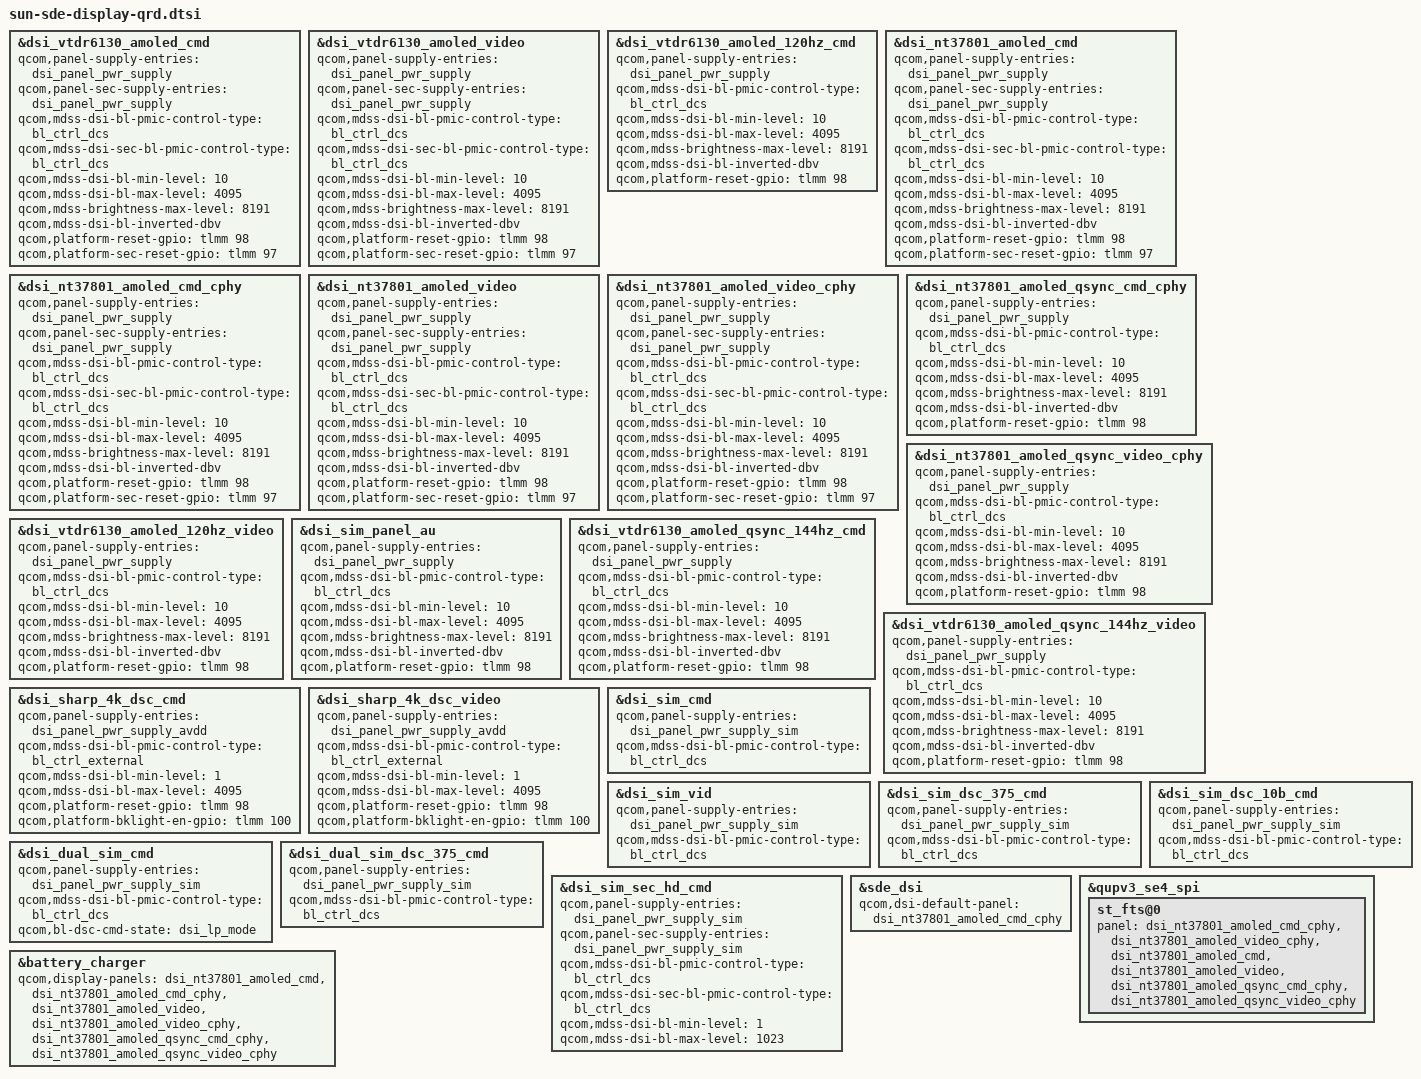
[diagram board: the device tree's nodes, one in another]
// SPDX-License-Identifier: BSD-3-Clause
/*
 * Copyright (c) 2023-2024, Qualcomm Innovation Center, Inc. All rights reserved.
 */

#include "sun-sde-display.dtsi"

&dsi_vtdr6130_amoled_cmd {
	qcom,panel-supply-entries = <&dsi_panel_pwr_supply>;
	qcom,panel-sec-supply-entries = <&dsi_panel_pwr_supply>;
	qcom,mdss-dsi-bl-pmic-control-type = "bl_ctrl_dcs";
	qcom,mdss-dsi-sec-bl-pmic-control-type = "bl_ctrl_dcs";
	qcom,mdss-dsi-bl-min-level = <10>;
	qcom,mdss-dsi-bl-max-level = <4095>;
	qcom,mdss-brightness-max-level = <8191>;
	qcom,mdss-dsi-bl-inverted-dbv;
	qcom,platform-reset-gpio = <&tlmm 98 0>;
	qcom,platform-sec-reset-gpio = <&tlmm 97 0>;
};

&dsi_vtdr6130_amoled_video {
	qcom,panel-supply-entries = <&dsi_panel_pwr_supply>;
	qcom,panel-sec-supply-entries = <&dsi_panel_pwr_supply>;
	qcom,mdss-dsi-bl-pmic-control-type = "bl_ctrl_dcs";
	qcom,mdss-dsi-sec-bl-pmic-control-type = "bl_ctrl_dcs";
	qcom,mdss-dsi-bl-min-level = <10>;
	qcom,mdss-dsi-bl-max-level = <4095>;
	qcom,mdss-brightness-max-level = <8191>;
	qcom,mdss-dsi-bl-inverted-dbv;
	qcom,platform-reset-gpio = <&tlmm 98 0>;
	qcom,platform-sec-reset-gpio = <&tlmm 97 0>;
};

&dsi_vtdr6130_amoled_120hz_cmd {
	qcom,panel-supply-entries = <&dsi_panel_pwr_supply>;
	qcom,mdss-dsi-bl-pmic-control-type = "bl_ctrl_dcs";
	qcom,mdss-dsi-bl-min-level = <10>;
	qcom,mdss-dsi-bl-max-level = <4095>;
	qcom,mdss-brightness-max-level = <8191>;
	qcom,mdss-dsi-bl-inverted-dbv;
	qcom,platform-reset-gpio = <&tlmm 98 0>;
};

&dsi_nt37801_amoled_cmd {
	qcom,panel-supply-entries = <&dsi_panel_pwr_supply>;
	qcom,panel-sec-supply-entries = <&dsi_panel_pwr_supply>;
	qcom,mdss-dsi-bl-pmic-control-type = "bl_ctrl_dcs";
	qcom,mdss-dsi-sec-bl-pmic-control-type = "bl_ctrl_dcs";
	qcom,mdss-dsi-bl-min-level = <10>;
	qcom,mdss-dsi-bl-max-level = <4095>;
	qcom,mdss-brightness-max-level = <8191>;
	qcom,mdss-dsi-bl-inverted-dbv;
	qcom,platform-reset-gpio = <&tlmm 98 0>;
	qcom,platform-sec-reset-gpio = <&tlmm 97 0>;
};

&dsi_nt37801_amoled_cmd_cphy {
	qcom,panel-supply-entries = <&dsi_panel_pwr_supply>;
	qcom,panel-sec-supply-entries = <&dsi_panel_pwr_supply>;
	qcom,mdss-dsi-bl-pmic-control-type = "bl_ctrl_dcs";
	qcom,mdss-dsi-sec-bl-pmic-control-type = "bl_ctrl_dcs";
	qcom,mdss-dsi-bl-min-level = <10>;
	qcom,mdss-dsi-bl-max-level = <4095>;
	qcom,mdss-brightness-max-level = <8191>;
	qcom,mdss-dsi-bl-inverted-dbv;
	qcom,platform-reset-gpio = <&tlmm 98 0>;
	qcom,platform-sec-reset-gpio = <&tlmm 97 0>;
};

&dsi_nt37801_amoled_video {
	qcom,panel-supply-entries = <&dsi_panel_pwr_supply>;
	qcom,panel-sec-supply-entries = <&dsi_panel_pwr_supply>;
	qcom,mdss-dsi-bl-pmic-control-type = "bl_ctrl_dcs";
	qcom,mdss-dsi-sec-bl-pmic-control-type = "bl_ctrl_dcs";
	qcom,mdss-dsi-bl-min-level = <10>;
	qcom,mdss-dsi-bl-max-level = <4095>;
	qcom,mdss-brightness-max-level = <8191>;
	qcom,mdss-dsi-bl-inverted-dbv;
	qcom,platform-reset-gpio = <&tlmm 98 0>;
	qcom,platform-sec-reset-gpio = <&tlmm 97 0>;
};

&dsi_nt37801_amoled_video_cphy {
	qcom,panel-supply-entries = <&dsi_panel_pwr_supply>;
	qcom,panel-sec-supply-entries = <&dsi_panel_pwr_supply>;
	qcom,mdss-dsi-bl-pmic-control-type = "bl_ctrl_dcs";
	qcom,mdss-dsi-sec-bl-pmic-control-type = "bl_ctrl_dcs";
	qcom,mdss-dsi-bl-min-level = <10>;
	qcom,mdss-dsi-bl-max-level = <4095>;
	qcom,mdss-brightness-max-level = <8191>;
	qcom,mdss-dsi-bl-inverted-dbv;
	qcom,platform-reset-gpio = <&tlmm 98 0>;
	qcom,platform-sec-reset-gpio = <&tlmm 97 0>;
};

&dsi_nt37801_amoled_qsync_cmd_cphy {
	qcom,panel-supply-entries = <&dsi_panel_pwr_supply>;
	qcom,mdss-dsi-bl-pmic-control-type = "bl_ctrl_dcs";
	qcom,mdss-dsi-bl-min-level = <10>;
	qcom,mdss-dsi-bl-max-level = <4095>;
	qcom,mdss-brightness-max-level = <8191>;
	qcom,mdss-dsi-bl-inverted-dbv;
	qcom,platform-reset-gpio = <&tlmm 98 0>;
};

&dsi_nt37801_amoled_qsync_video_cphy {
	qcom,panel-supply-entries = <&dsi_panel_pwr_supply>;
	qcom,mdss-dsi-bl-pmic-control-type = "bl_ctrl_dcs";
	qcom,mdss-dsi-bl-min-level = <10>;
	qcom,mdss-dsi-bl-max-level = <4095>;
	qcom,mdss-brightness-max-level = <8191>;
	qcom,mdss-dsi-bl-inverted-dbv;
	qcom,platform-reset-gpio = <&tlmm 98 0>;
};

&dsi_vtdr6130_amoled_120hz_video {
	qcom,panel-supply-entries = <&dsi_panel_pwr_supply>;
	qcom,mdss-dsi-bl-pmic-control-type = "bl_ctrl_dcs";
	qcom,mdss-dsi-bl-min-level = <10>;
	qcom,mdss-dsi-bl-max-level = <4095>;
	qcom,mdss-brightness-max-level = <8191>;
	qcom,mdss-dsi-bl-inverted-dbv;
	qcom,platform-reset-gpio = <&tlmm 98 0>;
};

&dsi_sim_panel_au {
	qcom,panel-supply-entries = <&dsi_panel_pwr_supply>;
	qcom,mdss-dsi-bl-pmic-control-type = "bl_ctrl_dcs";
	qcom,mdss-dsi-bl-min-level = <10>;
	qcom,mdss-dsi-bl-max-level = <4095>;
	qcom,mdss-brightness-max-level = <8191>;
	qcom,mdss-dsi-bl-inverted-dbv;
	qcom,platform-reset-gpio = <&tlmm 98 0>;
};

&dsi_vtdr6130_amoled_qsync_144hz_cmd {
	qcom,panel-supply-entries = <&dsi_panel_pwr_supply>;
	qcom,mdss-dsi-bl-pmic-control-type = "bl_ctrl_dcs";
	qcom,mdss-dsi-bl-min-level = <10>;
	qcom,mdss-dsi-bl-max-level = <4095>;
	qcom,mdss-brightness-max-level = <8191>;
	qcom,mdss-dsi-bl-inverted-dbv;
	qcom,platform-reset-gpio = <&tlmm 98 0>;
};

&dsi_vtdr6130_amoled_qsync_144hz_video {
	qcom,panel-supply-entries = <&dsi_panel_pwr_supply>;
	qcom,mdss-dsi-bl-pmic-control-type = "bl_ctrl_dcs";
	qcom,mdss-dsi-bl-min-level = <10>;
	qcom,mdss-dsi-bl-max-level = <4095>;
	qcom,mdss-brightness-max-level = <8191>;
	qcom,mdss-dsi-bl-inverted-dbv;
	qcom,platform-reset-gpio = <&tlmm 98 0>;
};

&dsi_sharp_4k_dsc_cmd {
	qcom,panel-supply-entries = <&dsi_panel_pwr_supply_avdd>;
	qcom,mdss-dsi-bl-pmic-control-type = "bl_ctrl_external";
	qcom,mdss-dsi-bl-min-level = <1>;
	qcom,mdss-dsi-bl-max-level = <4095>;
	qcom,platform-reset-gpio = <&tlmm 98 0>;
	qcom,platform-bklight-en-gpio = <&tlmm 100 0>;
};

&dsi_sharp_4k_dsc_video {
	qcom,panel-supply-entries = <&dsi_panel_pwr_supply_avdd>;
	qcom,mdss-dsi-bl-pmic-control-type = "bl_ctrl_external";
	qcom,mdss-dsi-bl-min-level = <1>;
	qcom,mdss-dsi-bl-max-level = <4095>;
	qcom,platform-reset-gpio = <&tlmm 98 0>;
	qcom,platform-bklight-en-gpio = <&tlmm 100 0>;
};

&dsi_sim_cmd {
	qcom,panel-supply-entries = <&dsi_panel_pwr_supply_sim>;
	qcom,mdss-dsi-bl-pmic-control-type = "bl_ctrl_dcs";
};

&dsi_sim_vid {
	qcom,panel-supply-entries = <&dsi_panel_pwr_supply_sim>;
	qcom,mdss-dsi-bl-pmic-control-type = "bl_ctrl_dcs";
};

&dsi_sim_dsc_375_cmd {
	qcom,panel-supply-entries = <&dsi_panel_pwr_supply_sim>;
	qcom,mdss-dsi-bl-pmic-control-type = "bl_ctrl_dcs";
};

&dsi_sim_dsc_10b_cmd {
	qcom,panel-supply-entries = <&dsi_panel_pwr_supply_sim>;
	qcom,mdss-dsi-bl-pmic-control-type = "bl_ctrl_dcs";
};

&dsi_dual_sim_cmd {
	qcom,panel-supply-entries = <&dsi_panel_pwr_supply_sim>;
	qcom,mdss-dsi-bl-pmic-control-type = "bl_ctrl_dcs";
	qcom,bl-dsc-cmd-state = "dsi_lp_mode";
};

&dsi_dual_sim_dsc_375_cmd {
	qcom,panel-supply-entries = <&dsi_panel_pwr_supply_sim>;
	qcom,mdss-dsi-bl-pmic-control-type = "bl_ctrl_dcs";
};

&dsi_sim_sec_hd_cmd {
	qcom,panel-supply-entries = <&dsi_panel_pwr_supply_sim>;
	qcom,panel-sec-supply-entries = <&dsi_panel_pwr_supply_sim>;
	qcom,mdss-dsi-bl-pmic-control-type = "bl_ctrl_dcs";
	qcom,mdss-dsi-sec-bl-pmic-control-type = "bl_ctrl_dcs";
	qcom,mdss-dsi-bl-min-level = <1>;
	qcom,mdss-dsi-bl-max-level = <1023>;
};

&sde_dsi {
	qcom,dsi-default-panel = <&dsi_nt37801_amoled_cmd_cphy>;
};

&qupv3_se4_spi {
	st_fts@0 {
		panel = <&dsi_nt37801_amoled_cmd_cphy
			&dsi_nt37801_amoled_video_cphy
			&dsi_nt37801_amoled_cmd
			&dsi_nt37801_amoled_video
			&dsi_nt37801_amoled_qsync_cmd_cphy
			&dsi_nt37801_amoled_qsync_video_cphy>;
	};
};

&battery_charger {
	qcom,display-panels = <&dsi_nt37801_amoled_cmd
				&dsi_nt37801_amoled_cmd_cphy
				&dsi_nt37801_amoled_video
				&dsi_nt37801_amoled_video_cphy
				&dsi_nt37801_amoled_qsync_cmd_cphy
				&dsi_nt37801_amoled_qsync_video_cphy>;
};
